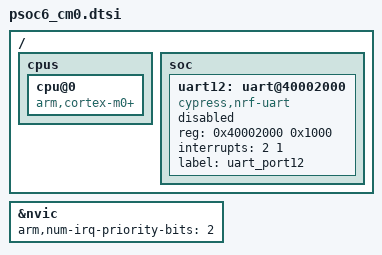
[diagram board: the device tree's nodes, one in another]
#include <arm/armv6-m.dtsi>
#include <cypress/psoc6.dtsi>

/ {
	cpus {
		cpu@0 {
			compatible = "arm,cortex-m0+";
		};

		/delete-node/ cpu@1;
	};

	soc {
		/delete-node/ uart5;

		uart12: uart@40002000 {
			compatible = "cypress,nrf-uart";
			reg = <0x40002000 0x1000>;
			interrupts = <2 1>;
			status = "disabled";
			label = "uart_port12";
		};
	};
};

&nvic {
	arm,num-irq-priority-bits = <2>;
};
